# ATmega6490P device description
Architecture: AVR8; Family: megaAVR
Registers are 8-bit, access not given, no defined reset value unless marked. A register's access mark holds for its fields unless they carry their own. Offsets are from the block's base; [hi:lo] are bit positions.

## CPU — CPU Registers
Instances: CPU 0x00
Parameters: CORE_VERSION=V2E
0x3E GPIOR0 — General Purpose IO Register 0
0x4A GPIOR1 — General Purpose IO Register 1
0x4B GPIOR2 — General Purpose IO Register 2
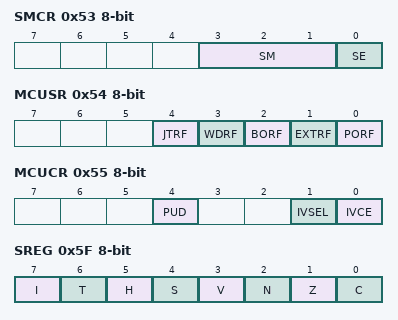
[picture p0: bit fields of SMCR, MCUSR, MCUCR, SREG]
0x53 SMCR — Sleep Mode Control Register
  [3:1] SM — Sleep Mode Select bits
    0=IDLE; 1=ADC (ADC Noise Reduction (If Available)); 2=PDOWN (Power Down); 3=PSAVE (Power Save); 6=STDBY (Standby)
  [0] SE — Sleep Enable
0x54 MCUSR — MCU Status Register
  [4] JTRF — JTAG Reset Flag
  [3] WDRF — Watchdog Reset Flag
  [2] BORF — Brown-out Reset Flag
  [1] EXTRF — External Reset Flag
  [0] PORF — Power-on reset flag
0x55 MCUCR — MCU Control Register
  [4] PUD — Pull-up disable
  [1] IVSEL — Interrupt Vector Select
  [0] IVCE — Interrupt Vector Change Enable
0x5D SP 16-bit — Stack Pointer
0x5F SREG — Status Register
  [7] I — Global Interrupt Enable
  [6] T — Bit Copy Storage
  [5] H — Half Carry Flag
  [4] S — Sign Bit
  [3] V — Two's Complement Overflow Flag
  [2] N — Negative Flag
  [1] Z — Zero Flag
  [0] C — Carry Flag
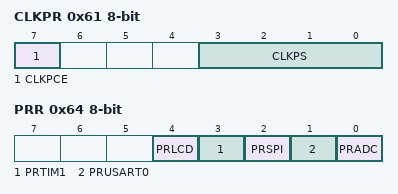
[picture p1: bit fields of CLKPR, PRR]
0x61 CLKPR — Clock Prescale Register
  [7] CLKPCE — Clock Prescaler Change Enable
  [3:0] CLKPS — Clock Prescaler Select Bits
    0=1; 1=2; 2=4; 3=8; 4=16; 5=32; 6=64; 7=128; 8=256
0x64 PRR — Power Reduction Register
  [4] PRLCD — Power Reduction LCD
  [3] PRTIM1 — Power Reduction Timer/Counter1
  [2] PRSPI — Power Reduction Serial Peripheral Interface
  [1] PRUSART0 — Power Reduction USART
  [0] PRADC — Power Reduction ADC
0x66 OSCCAL — Oscillator Calibration Value
  [7:0] OSCCAL — Oscillator Calibration
Value list OSCCAL_VALUE_ADDRESSES: 0=8_0_MHz

## JTAG — JTAG Interface
Instances: JTAG 0x00
0x51 OCDR — On-Chip Debug Related Register in I/O Memory
0x54 MCUSR — MCU Status Register
  [4] JTRF — JTAG Reset Flag
0x55 MCUCR — MCU Control Register
  [7] JTD — JTAG Interface Disable

## EEPROM
Instances: EEPROM 0x00
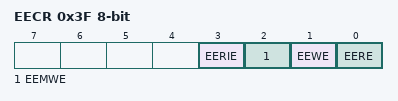
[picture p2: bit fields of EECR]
0x3F EECR — EEPROM Control Register
  [3] EERIE — EEPROM Ready Interrupt Enable
  [2] EEMWE — EEPROM Master Write Enable
  [1] EEWE — EEPROM Write Enable
  [0] EERE — EEPROM Read Enable
0x40 EEDR — EEPROM Data Register
0x41 EEAR 16-bit bits used 10:0 — EEPROM Read/Write Access Bytes

## PORTA — I/O Port
Instances: PORTA 0x00
0x20 PINA — Port A Input Pins
0x21 DDRA — Port A Data Direction Register
0x22 PORTA — Port A Data Register

## PORTB — I/O Port
Instances: PORTB 0x00
0x23 PINB — Port B Input Pins
0x24 DDRB — Port B Data Direction Register
0x25 PORTB — Port B Data Register

## PORTC — I/O Port
Instances: PORTC 0x00
0x26 PINC — Port C Input Pins
0x27 DDRC — Port C Data Direction Register
0x28 PORTC — Port C Data Register

## PORTD — I/O Port
Instances: PORTD 0x00
0x29 PIND — Port D Input Pins
0x2A DDRD — Port D Data Direction Register
0x2B PORTD — Port D Data Register

## PORTE — I/O Port
Instances: PORTE 0x00
0x2C PINE — Input Pins, Port E
0x2D DDRE — Data Direction Register, Port E
0x2E PORTE — Data Register, Port E

## PORTF — I/O Port
Instances: PORTF 0x00
0x2F PINF — Input Pins, Port F
0x30 DDRF — Data Direction Register, Port F
0x31 PORTF — Data Register, Port F

## PORTG — I/O Port
Instances: PORTG 0x00
0x32 PING bits used 5:0 — Port G Input Pins
0x33 DDRG bits used 4:0 — Port G Data Direction Register
0x34 PORTG bits used 4:0 — Port G Data Register

## PORTH — I/O Port
Instances: PORTH 0x00
0xD8 PINH — PORT H Input Pins
0xD9 DDRH — PORT H Data Direction Register
0xDA PORTH — PORT H Data Register

## PORTJ — I/O Port
Instances: PORTJ 0x00
0xDB PINJ bits used 6:0 — PORT J Input Pins
0xDC DDRJ bits used 6:0 — PORT J Data Direction Register
0xDD PORTJ bits used 6:0 — PORT J Data Register
